AUTOSAR XML (schema 4-2-2)
package /AUTOLIV/SoftwareComponents/RCM
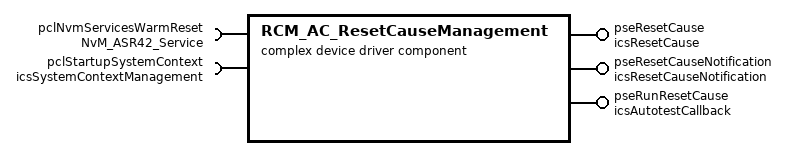
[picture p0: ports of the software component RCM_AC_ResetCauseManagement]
  complex device driver sw component type RCM_AC_ResetCauseManagement: category=MCAL
    require port pclNvmServicesWarmReset: required-interface=NvM_ASR42_Service
      required-com-specs:
        GetErrorStatus
        SetDataIndex
        GetDataIndex
        SetRamBlockStatus
        ReadBlock
        WriteBlock
        RestoreBlockDefaults
        EraseBlock
        InvalidateNvBlock
    require port pclStartupSystemContext: required-interface=icsSystemContextManagement
      required-com-specs:
        GetLastTensionningState
        RestoreSystemContext
        GetLastKL30LostStatus
        SuperviseKL30bg
        ManageSystemContextStorage
    provide port pseResetCause: provided-interface=icsResetCause
      provided-com-specs:
        operation=DetermineResetCause, queue-length=1
        operation=ConfirmResetCause, queue-length=1
        operation=GetResetCause, queue-length=1
    provide port pseResetCauseNotification: server-com-spec{operation=NotifyResetCause, queue-length=1}, provided-interface=icsResetCauseNotification  # RCM port for RCM to be notified by other SW modules of the cause which will lead to reset
    provide port pseRunResetCause: server-com-spec{operation=AutotestCallback, queue-length=1}, provided-interface=icsAutotestCallback
